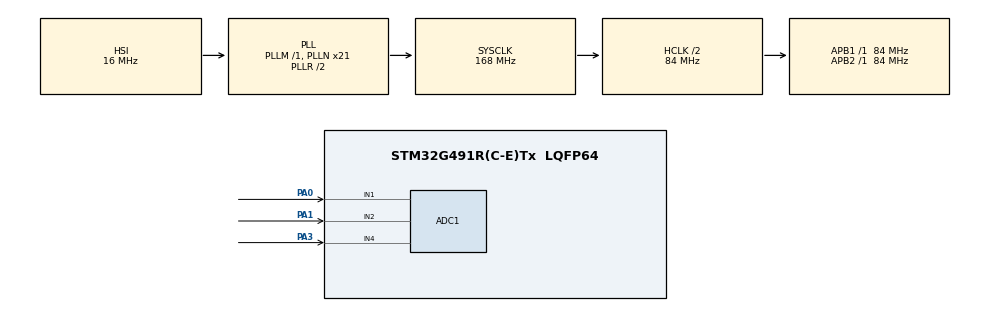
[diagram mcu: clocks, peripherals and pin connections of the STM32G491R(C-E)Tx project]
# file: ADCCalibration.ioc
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ADC1.Channel-0\#ChannelRegularConversion=ADC_CHANNEL_1
ADC1.NbrOfConversionFlag=1
ADC1.OffsetNumber-0\#ChannelRegularConversion=ADC_OFFSET_NONE
ADC1.Rank-0\#ChannelRegularConversion=1
ADC1.SamplingTime-0\#ChannelRegularConversion=ADC_SAMPLETIME_2CYCLES_5
ADC1.master=1
Mcu.Family=STM32G4
Mcu.Name=STM32G491R(C-E)Tx
Mcu.Package=LQFP64
NVIC.PriorityGroup=NVIC_PRIORITYGROUP_4
PA0.Mode=IN1-Single-Ended
PA0.Signal=ADC1_IN1
PA1.Mode=IN2-Single-Ended
PA1.Signal=ADC1_IN2
PA3.Mode=IN4-Single-Ended
PA3.Signal=ADC1_IN4
ProjectManager.HeapSize=0x200
ProjectManager.StackSize=0x400
ProjectManager.TargetToolchain=STM32CubeIDE
RCC.ADC12Freq_Value=168000000
RCC.ADC345Freq_Value=168000000
RCC.AHBCLKDivider=RCC_SYSCLK_DIV2
RCC.AHBFreq_Value=84000000
RCC.APB1Freq_Value=84000000
RCC.APB1TimFreq_Value=84000000
RCC.APB2Freq_Value=84000000
RCC.APB2TimFreq_Value=84000000
RCC.CortexFreq_Value=84000000
RCC.EXTERNAL_CLOCK_VALUE=12288000
RCC.HCLKFreq_Value=84000000
RCC.HSE_VALUE=8000000
RCC.HSI48_VALUE=48000000
RCC.HSI_VALUE=16000000
RCC.LSE_VALUE=32768
RCC.PLLN=21
RCC.SYSCLKFreq_VALUE=168000000
RCC.SYSCLKSource=RCC_SYSCLKSOURCE_PLLCLK
RCC.VCOOutputFreq_Value=336000000
VP_SYS_VS_DBSignals.Mode=DisableDeadBatterySignals
board=custom

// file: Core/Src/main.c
/* USER CODE BEGIN Header */
/**
  ******************************************************************************
  * @file           : main.c
  * @brief          : Main program body
  ******************************************************************************
  * @attention
  *
  * Copyright (c) 2024 STMicroelectronics.
  * All rights reserved.
  *
  * This software is licensed under terms that can be found in the LICENSE file
  * in the root directory of this software component.
  * If no LICENSE file comes with this software, it is provided AS-IS.
  *
  ******************************************************************************
  */
/* USER CODE END Header */
#include "main.h"

ADC_HandleTypeDef hadc1;

/* USER CODE BEGIN PV */
uint32_t OffsetAcc = 0;
uint32_t GainAcc = 0;
uint32_t ADCValue;
float V;
/* USER CODE END PV */

void SystemClock_Config(void);
static void MX_GPIO_Init(void);
static void MX_ADC1_Init(void);

int main(void)
{

  /* USER CODE BEGIN 1 */
	ADC_ChannelConfTypeDef sConfig ={0};
  /* USER CODE END 1 */

  /* MCU Configuration--------------------------------------------------------*/

  /* Reset of all peripherals, Initializes the Flash interface and the Systick. */
  HAL_Init();

  /* Configure the system clock */
  SystemClock_Config();

  /* Initialize all configured peripherals */
  MX_GPIO_Init();
  MX_ADC1_Init();
  /* USER CODE BEGIN 2 */

  //Get Offset Accuracy
  //GND connects with ADC_IN1
  //Init sConfig for ADC_IN1 is in MX_ADC1_Init
  sConfig.Channel = ADC_CHANNEL_1;
  sConfig.Rank = 1;
  sConfig.SamplingTime = ADC_SAMPLETIME_2CYCLES_5;
  HAL_ADC_ConfigChannel(&hadc1, &sConfig);
  HAL_ADC_Start(&hadc1);
  HAL_ADC_PollForConversion(&hadc1, 1000);
  OffsetAcc = HAL_ADC_GetValue(&hadc1);
  HAL_ADC_Stop(&hadc1);
  hadc1.Instance->SQR1 = 0;

  //Get Gain Accuracy
  //Vdd connects with ADC_IN2
  sConfig.Channel = ADC_CHANNEL_2;
  sConfig.Rank = 1;
  sConfig.SamplingTime = ADC_SAMPLETIME_2CYCLES_5;
  HAL_ADC_ConfigChannel(&hadc1, &sConfig);
  HAL_ADC_Start(&hadc1);
  HAL_ADC_PollForConversion(&hadc1,1000);
  GainAcc = HAL_ADC_GetValue(&hadc1);
  HAL_ADC_Stop(&hadc1);
  hadc1.Instance->SQR1 = 0;

  //Get ADC and conver to calibrated value
  //The ADC port connects with ADC_IN4
  sConfig.Channel = ADC_CHANNEL_4;
  sConfig.Rank = 1;
  sConfig.SamplingTime = ADC_SAMPLETIME_2CYCLES_5;
  HAL_ADC_ConfigChannel(&hadc1, &sConfig);

  /* USER CODE END 2 */

  /* Infinite loop */
  while (1)
  {

    /* USER CODE BEGIN 3 */
	  // Get ADC Value
	  HAL_ADC_Start(&hadc1);
	  HAL_ADC_PollForConversion(&hadc1, 1000);
	  ADCValue = HAL_ADC_GetValue(&hadc1);
	  HAL_ADC_Stop(&hadc1);
	  // Get Calibrated Voltage
	  V = 3.3F*((float)ADCValue - (float)OffsetAcc)/((float)GainAcc - (float)OffsetAcc);
	  __NOP();
  }
  /* USER CODE END 3 */
}

void SystemClock_Config(void)
{
  RCC_OscInitTypeDef RCC_OscInitStruct = {0};
  RCC_ClkInitTypeDef RCC_ClkInitStruct = {0};

  /** Configure the main internal regulator output voltage
  */
  HAL_PWREx_ControlVoltageScaling(PWR_REGULATOR_VOLTAGE_SCALE1);

  /** Initializes the RCC Oscillators according to the specified parameters
  * in the RCC_OscInitTypeDef structure.
  */
  RCC_OscInitStruct.OscillatorType = RCC_OSCILLATORTYPE_HSI;
  RCC_OscInitStruct.HSIState = RCC_HSI_ON;
  RCC_OscInitStruct.HSICalibrationValue = RCC_HSICALIBRATION_DEFAULT;
  RCC_OscInitStruct.PLL.PLLState = RCC_PLL_ON;
  RCC_OscInitStruct.PLL.PLLSource = RCC_PLLSOURCE_HSI;
  RCC_OscInitStruct.PLL.PLLM = RCC_PLLM_DIV1;
  RCC_OscInitStruct.PLL.PLLN = 21;
  RCC_OscInitStruct.PLL.PLLP = RCC_PLLP_DIV2;
  RCC_OscInitStruct.PLL.PLLQ = RCC_PLLQ_DIV2;
  RCC_OscInitStruct.PLL.PLLR = RCC_PLLR_DIV2;
  if (HAL_RCC_OscConfig(&RCC_OscInitStruct) != HAL_OK)
  {
    Error_Handler();
  }

  /** Initializes the CPU, AHB and APB buses clocks
  */
  RCC_ClkInitStruct.ClockType = RCC_CLOCKTYPE_HCLK|RCC_CLOCKTYPE_SYSCLK
                              |RCC_CLOCKTYPE_PCLK1|RCC_CLOCKTYPE_PCLK2;
  RCC_ClkInitStruct.SYSCLKSource = RCC_SYSCLKSOURCE_PLLCLK;
  RCC_ClkInitStruct.AHBCLKDivider = RCC_SYSCLK_DIV2;
  RCC_ClkInitStruct.APB1CLKDivider = RCC_HCLK_DIV1;
  RCC_ClkInitStruct.APB2CLKDivider = RCC_HCLK_DIV1;

  if (HAL_RCC_ClockConfig(&RCC_ClkInitStruct, FLASH_LATENCY_2) != HAL_OK)
  {
    Error_Handler();
  }
}

static void MX_ADC1_Init(void)
{

  ADC_MultiModeTypeDef multimode = {0};
  ADC_ChannelConfTypeDef sConfig = {0};

  /** Common config
  */
  hadc1.Instance = ADC1;
  hadc1.Init.ClockPrescaler = ADC_CLOCK_SYNC_PCLK_DIV2;
  hadc1.Init.Resolution = ADC_RESOLUTION_12B;
  hadc1.Init.DataAlign = ADC_DATAALIGN_RIGHT;
  hadc1.Init.GainCompensation = 0;
  hadc1.Init.ScanConvMode = ADC_SCAN_DISABLE;
  hadc1.Init.EOCSelection = ADC_EOC_SINGLE_CONV;
  hadc1.Init.LowPowerAutoWait = DISABLE;
  hadc1.Init.ContinuousConvMode = DISABLE;
  hadc1.Init.NbrOfConversion = 1;
  hadc1.Init.DiscontinuousConvMode = DISABLE;
  hadc1.Init.ExternalTrigConv = ADC_SOFTWARE_START;
  hadc1.Init.ExternalTrigConvEdge = ADC_EXTERNALTRIGCONVEDGE_NONE;
  hadc1.Init.DMAContinuousRequests = DISABLE;
  hadc1.Init.Overrun = ADC_OVR_DATA_PRESERVED;
  hadc1.Init.OversamplingMode = DISABLE;
  if (HAL_ADC_Init(&hadc1) != HAL_OK)
  {
    Error_Handler();
  }

  /** Configure the ADC multi-mode
  */
  multimode.Mode = ADC_MODE_INDEPENDENT;
  if (HAL_ADCEx_MultiModeConfigChannel(&hadc1, &multimode) != HAL_OK)
  {
    Error_Handler();
  }

  /** Configure Regular Channel
  */
  sConfig.Channel = ADC_CHANNEL_1;
  sConfig.Rank = ADC_REGULAR_RANK_1;
  sConfig.SamplingTime = ADC_SAMPLETIME_2CYCLES_5;
  sConfig.SingleDiff = ADC_SINGLE_ENDED;
  sConfig.OffsetNumber = ADC_OFFSET_NONE;
  sConfig.Offset = 0;
  if (HAL_ADC_ConfigChannel(&hadc1, &sConfig) != HAL_OK)
  {
    Error_Handler();
  }

}

static void MX_GPIO_Init(void)
{

  /* GPIO Ports Clock Enable */
  __HAL_RCC_GPIOA_CLK_ENABLE();

}

void Error_Handler(void)
{
  __disable_irq();
  while (1)
  {
  }
}
